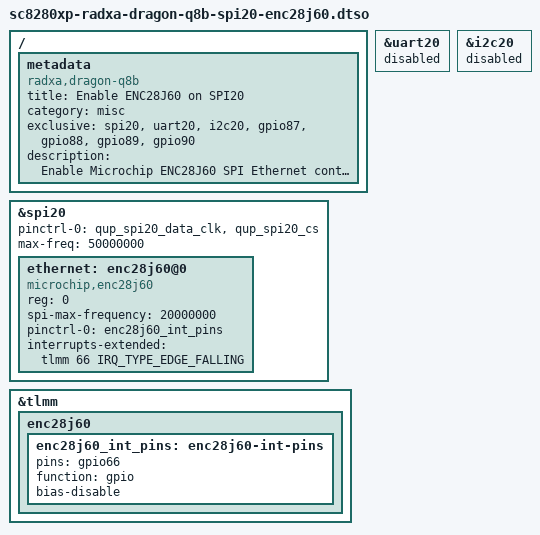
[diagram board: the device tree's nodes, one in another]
// SPDX-License-Identifier: BSD-3-Clause
/*
 * Copyright (c) 2026 Radxa Computer (Shenzhen) Co., Ltd.
 */

/dts-v1/;
/plugin/;

#include <dt-bindings/interrupt-controller/irq.h>

/ {
	metadata {
		title = "Enable ENC28J60 on SPI20";
		compatible = "radxa,dragon-q8b";
		category = "misc";
		exclusive = "spi20", "uart20", "i2c20", "gpio87", "gpio88", "gpio89", "gpio90";
		description = "Enable Microchip ENC28J60 SPI Ethernet controller on SPI20.
INT=13";
	};
};

&uart20 {
	status = "disabled";
};

&i2c20 {
	status = "disabled";
};

&spi20 {
	pinctrl-0 = <&qup_spi20_data_clk>, <&qup_spi20_cs>;
	pinctrl-names = "default";
	max-freq = <50000000>;
	
	status = "okay";

	ethernet: enc28j60@0 {
		compatible = "microchip,enc28j60";
		reg = <0>;
		spi-max-frequency = <20000000>;

		pinctrl-names = "default";
		pinctrl-0 = <&enc28j60_int_pins>;

		interrupts-extended = <&tlmm 66 IRQ_TYPE_EDGE_FALLING>;
	};
};

&tlmm {
	enc28j60 {
		enc28j60_int_pins: enc28j60-int-pins {
			pins = "gpio66";
			function = "gpio";
			bias-disable;
		};
	};
};
